# PIC32MX340F512H register map
Vendor: Microchip
Registers are 32-bit, read-write, reset 0x0 unless marked. A register's access mark holds for its fields unless they carry their own. Addresses are absolute, and some are shared; only a register's first bit layout is shown; [hi:lo] are bit positions.

## BMX
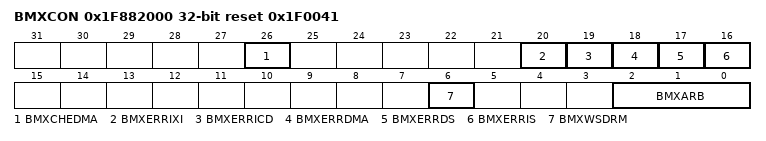
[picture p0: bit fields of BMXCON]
0x1F882000 BMXCON reset 0x1F0041
  [26] BMXCHEDMA, [20] BMXERRIXI, [19] BMXERRICD, [18] BMXERRDMA, [17] BMXERRDS, [16] BMXERRIS, [6] BMXWSDRM, [2:0] BMXARB
0x1F882010 BMXDKPBA
0x1F882020 BMXDUDBA
0x1F882030 BMXDUPBA
0x1F882040 BMXDRMSZ ro reset 0x20000
0x1F882050 BMXPUPBA
0x1F882060 BMXPFMSZ ro reset 0x80000
0x1F882070 BMXBOOTSZ ro reset 0x3000

## dma_bvci
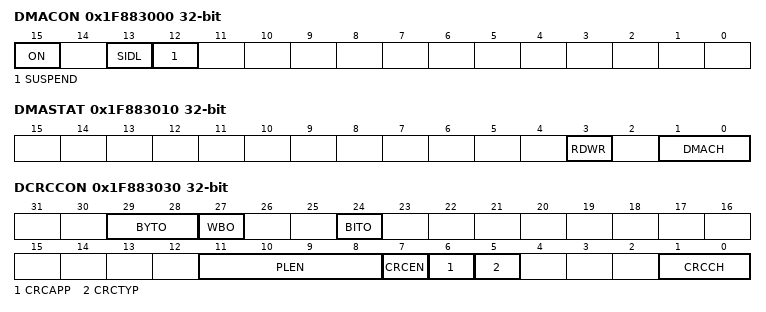
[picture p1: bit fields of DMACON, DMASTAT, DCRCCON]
0x1F883000 DMACON reset not defined — (power-on value ----------------00x0------------)
  [15] ON, [13] SIDL, [12] SUSPEND
0x1F883010 DMASTAT reset not defined — (power-on value ----------------------------0-xx)
  [3] RDWR, [1:0] DMACH
0x1F883020 DMAADDR ro
0x1F883030 DCRCCON reset not defined — (power-on value --xxx--x------------xxxx00x---xx)
  [29:28] BYTO, [27] WBO, [24] BITO, [11:8] PLEN, [7] CRCEN, [6] CRCAPP, [5] CRCTYP, [1:0] CRCCH
0x1F883040 DCRCDATA
0x1F883050 DCRCXOR

## DMAC0
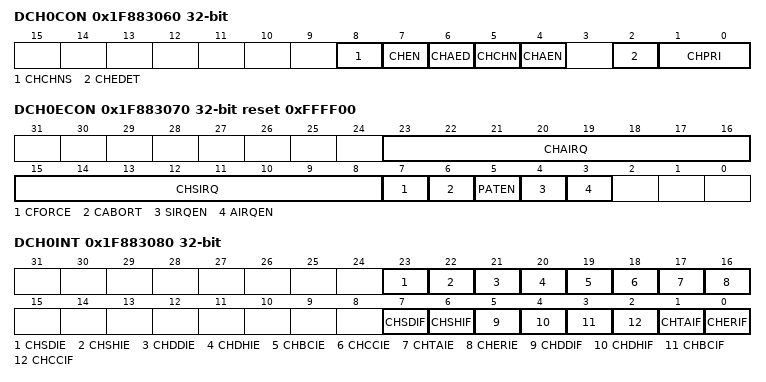
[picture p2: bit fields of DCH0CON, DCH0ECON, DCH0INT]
0x1F883060 DCH0CON
  [8] CHCHNS, [7] CHEN, [6] CHAED, [5] CHCHN, [4] CHAEN, [2] CHEDET ro, [1:0] CHPRI
0x1F883070 DCH0ECON reset 0xFFFF00
  [23:16] CHAIRQ
  [15:8] CHSIRQ
  [7] CFORCE — (can only be set)
  [6] CABORT — (can only be set)
  [5] PATEN
  [4] SIRQEN
  [3] AIRQEN
0x1F883080 DCH0INT
  [23] CHSDIE, [22] CHSHIE, [21] CHDDIE, [20] CHDHIE, [19] CHBCIE, [18] CHCCIE, [17] CHTAIE, [16] CHERIE, [7] CHSDIF, [6] CHSHIF, [5] CHDDIF, [4] CHDHIF, [3] CHBCIF, [2] CHCCIF, [1] CHTAIF, [0] CHERIF
0x1F883090 DCH0SSA reset not defined — (power-on value xxxxxxxxxxxxxxxxxxxxxxxxxxxxxxxx)
0x1F8830A0 DCH0DSA reset not defined — (power-on value xxxxxxxxxxxxxxxxxxxxxxxxxxxxxxxx)
0x1F8830B0 DCH0SSIZ reset not defined — (power-on value ----------------xxxxxxxxxxxxxxxx)
  [15:0] CHSSIZ
0x1F8830C0 DCH0DSIZ reset not defined — (power-on value ----------------xxxxxxxxxxxxxxxx)
  [15:0] CHDSIZ
0x1F8830D0 DCH0SPTR reset not defined — (power-on value ----------------xxxxxxxxxxxxxxxx)
  [15:0] CHSPTR
0x1F8830E0 DCH0DPTR ro
  [15:0] CHDPTR
0x1F8830F0 DCH0CSIZ reset not defined — (power-on value ----------------xxxxxxxxxxxxxxxx)
  [15:0] CHCSIZ
0x1F883100 DCH0CPTR reset not defined — (power-on value ----------------xxxxxxxxxxxxxxxx)
  [15:0] CHCPTR
0x1F883110 DCH0DAT reset not defined — (power-on value ------------------------xxxxxxxx)
  [7:0] DCHPDAT

## DMAC1
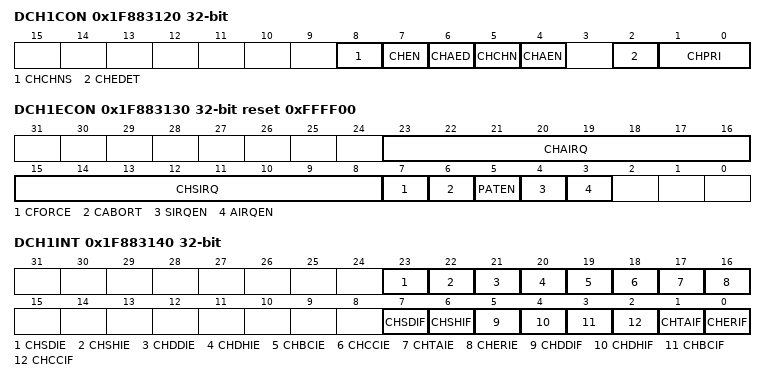
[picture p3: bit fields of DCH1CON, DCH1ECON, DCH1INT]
0x1F883120 DCH1CON
  [8] CHCHNS, [7] CHEN, [6] CHAED, [5] CHCHN, [4] CHAEN, [2] CHEDET ro, [1:0] CHPRI
0x1F883130 DCH1ECON reset 0xFFFF00
  [23:16] CHAIRQ
  [15:8] CHSIRQ
  [7] CFORCE — (can only be set)
  [6] CABORT — (can only be set)
  [5] PATEN
  [4] SIRQEN
  [3] AIRQEN
0x1F883140 DCH1INT
  [23] CHSDIE, [22] CHSHIE, [21] CHDDIE, [20] CHDHIE, [19] CHBCIE, [18] CHCCIE, [17] CHTAIE, [16] CHERIE, [7] CHSDIF, [6] CHSHIF, [5] CHDDIF, [4] CHDHIF, [3] CHBCIF, [2] CHCCIF, [1] CHTAIF, [0] CHERIF
0x1F883150 DCH1SSA reset not defined — (power-on value xxxxxxxxxxxxxxxxxxxxxxxxxxxxxxxx)
0x1F883160 DCH1DSA reset not defined — (power-on value xxxxxxxxxxxxxxxxxxxxxxxxxxxxxxxx)
0x1F883170 DCH1SSIZ reset not defined — (power-on value ----------------xxxxxxxxxxxxxxxx)
  [15:0] CHSSIZ
0x1F883180 DCH1DSIZ reset not defined — (power-on value ----------------xxxxxxxxxxxxxxxx)
  [15:0] CHDSIZ
0x1F883190 DCH1SPTR reset not defined — (power-on value ----------------xxxxxxxxxxxxxxxx)
  [15:0] CHSPTR
0x1F8831A0 DCH1DPTR ro
  [15:0] CHDPTR
0x1F8831B0 DCH1CSIZ reset not defined — (power-on value ----------------xxxxxxxxxxxxxxxx)
  [15:0] CHCSIZ
0x1F8831C0 DCH1CPTR reset not defined — (power-on value ----------------xxxxxxxxxxxxxxxx)
  [15:0] CHCPTR
0x1F8831D0 DCH1DAT reset not defined — (power-on value ------------------------xxxxxxxx)
  [7:0] DCHPDAT

## DMAC2
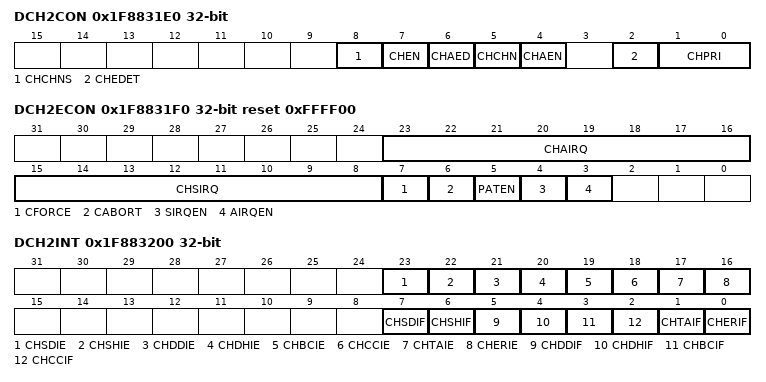
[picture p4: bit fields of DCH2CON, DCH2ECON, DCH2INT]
0x1F8831E0 DCH2CON
  [8] CHCHNS, [7] CHEN, [6] CHAED, [5] CHCHN, [4] CHAEN, [2] CHEDET ro, [1:0] CHPRI
0x1F8831F0 DCH2ECON reset 0xFFFF00
  [23:16] CHAIRQ
  [15:8] CHSIRQ
  [7] CFORCE — (can only be set)
  [6] CABORT — (can only be set)
  [5] PATEN
  [4] SIRQEN
  [3] AIRQEN
0x1F883200 DCH2INT
  [23] CHSDIE, [22] CHSHIE, [21] CHDDIE, [20] CHDHIE, [19] CHBCIE, [18] CHCCIE, [17] CHTAIE, [16] CHERIE, [7] CHSDIF, [6] CHSHIF, [5] CHDDIF, [4] CHDHIF, [3] CHBCIF, [2] CHCCIF, [1] CHTAIF, [0] CHERIF
0x1F883210 DCH2SSA reset not defined — (power-on value xxxxxxxxxxxxxxxxxxxxxxxxxxxxxxxx)
0x1F883220 DCH2DSA reset not defined — (power-on value xxxxxxxxxxxxxxxxxxxxxxxxxxxxxxxx)
0x1F883230 DCH2SSIZ reset not defined — (power-on value ----------------xxxxxxxxxxxxxxxx)
  [15:0] CHSSIZ
0x1F883240 DCH2DSIZ reset not defined — (power-on value ----------------xxxxxxxxxxxxxxxx)
  [15:0] CHDSIZ
0x1F883250 DCH2SPTR reset not defined — (power-on value ----------------xxxxxxxxxxxxxxxx)
  [15:0] CHSPTR
0x1F883260 DCH2DPTR ro
  [15:0] CHDPTR
0x1F883270 DCH2CSIZ reset not defined — (power-on value ----------------xxxxxxxxxxxxxxxx)
  [15:0] CHCSIZ
0x1F883280 DCH2CPTR reset not defined — (power-on value ----------------xxxxxxxxxxxxxxxx)
  [15:0] CHCPTR
0x1F883290 DCH2DAT reset not defined — (power-on value ------------------------xxxxxxxx)
  [7:0] DCHPDAT
